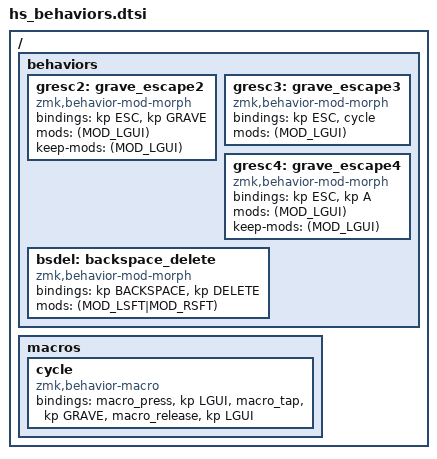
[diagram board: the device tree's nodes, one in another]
/*
 * Copyright (c) 2023 The ZMK Contributors
 *
 * SPDX-License-Identifier: MIT
 */

/ {
   
    behaviors {
        gresc2: grave_escape2 {
            compatible = "zmk,behavior-mod-morph";
            #binding-cells = <0>;
            bindings = <&kp ESC>, <&kp GRAVE>;
            mods = <(MOD_LGUI)>;
            keep-mods = <(MOD_LGUI)>;
        	};
        gresc3: grave_escape3 {
            compatible = "zmk,behavior-mod-morph";
            #binding-cells = <0>;
            bindings = <&kp ESC>, <&cycle>;
            mods = <(MOD_LGUI)>;
        	};
		gresc4: grave_escape4 {
            compatible = "zmk,behavior-mod-morph";
            #binding-cells = <0>;
            bindings = <&kp ESC>, <&kp A>;
            mods = <(MOD_LGUI)>;
            keep-mods = <(MOD_LGUI)>;
        	};
        bsdel: backspace_delete {
            compatible = "zmk,behavior-mod-morph";
            #binding-cells = <0>;
            bindings = <&kp BACKSPACE>, <&kp DELETE>;
            mods = <(MOD_LSFT|MOD_RSFT)>;
        	};
    };
    
    macros {
        cycle: cycle {
            compatible = "zmk,behavior-macro";
            #binding-cells = <0>;
            bindings = 
                <&macro_press &kp LGUI>,
				<&macro_tap &kp GRAVE>,
				<&macro_release &kp LGUI>;
    		};
    };
};
